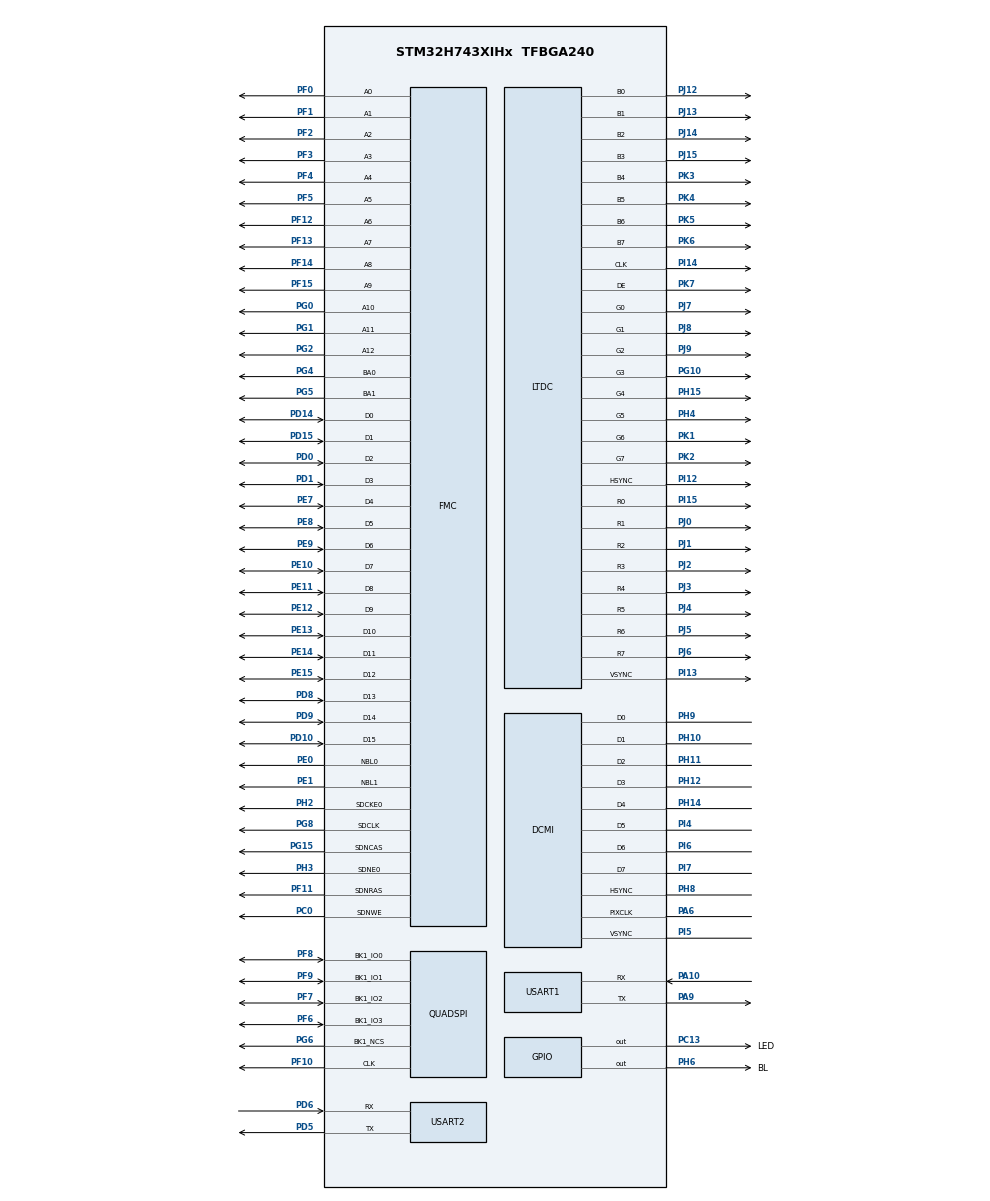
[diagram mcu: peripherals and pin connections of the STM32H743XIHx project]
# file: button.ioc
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CORTEX_M7.AccessPermission-Cortex_Memory_Protection_Unit_Region0_Settings=MPU_REGION_FULL_ACCESS
CORTEX_M7.AccessPermission_Spec=MPU_REGION_FULL_ACCESS
CORTEX_M7.BaseAddress-Cortex_Memory_Protection_Unit_Region0_Settings=0xC0000000
CORTEX_M7.BaseAddress_Spec=0xC0000000
CORTEX_M7.CPU_DCache=Enabled
CORTEX_M7.CPU_ICache=Enabled
CORTEX_M7.DisableExec_Spec=MPU_INSTRUCTION_ACCESS_ENABLE
CORTEX_M7.Enable-Cortex_Memory_Protection_Unit_Region0_Settings=MPU_REGION_ENABLE
CORTEX_M7.IsCacheable-Cortex_Memory_Protection_Unit_Region0_Settings=MPU_ACCESS_CACHEABLE
CORTEX_M7.IsCacheable_Spec=MPU_ACCESS_CACHEABLE
CORTEX_M7.IsShareable_Spec=MPU_ACCESS_NOT_SHAREABLE
CORTEX_M7.MPU_Control=MPU_HFNMI_PRIVDEF
CORTEX_M7.Size-Cortex_Memory_Protection_Unit_Region0_Settings=MPU_REGION_SIZE_32MB
CORTEX_M7.Size_Spec=MPU_REGION_SIZE_32MB
CORTEX_M7.SubRegionDisable_Spec=0x0
DCMI.PCKPolarity=DCMI_PCKPOLARITY_RISING
DMA2D.ColorMode=DMA2D_OUTPUT_RGB565
FMC.CASLatency1=FMC_SDRAM_CAS_LATENCY_3
FMC.ColumnBitsNumber1=FMC_SDRAM_COLUMN_BITS_NUM_9
FMC.ExitSelfRefreshDelay1=7
FMC.LoadToActiveDelay1=2
FMC.RCDDelay1=2 
FMC.RPDelay1=2
FMC.ReadBurst1=FMC_SDRAM_RBURST_ENABLE
FMC.ReadPipeDelay1=FMC_SDRAM_RPIPE_DELAY_1
FMC.RowCycleDelay1=7
FMC.SDClockPeriod1=FMC_SDRAM_CLOCK_PERIOD_2
FMC.SelfRefreshTime1=4
FMC.WriteRecoveryTime1=3
FREERTOS.Tasks01=TouchGFX_Task,0,4096,Start_TouchGFX_Task,Default,NULL,Dynamic,NULL,NULL;LED,-2,128,StartTaskLED,Default,NULL,Dynamic,NULL,NULL
FREERTOS.configMAX_PRIORITIES=14
FREERTOS.configTOTAL_HEAP_SIZE=32768
LTDC.ActiveW=800
LTDC.Alpha_L0=255
LTDC.FBStartAdress_L0=0xC0000000
LTDC.HBP=80
LTDC.HFP=200
LTDC.HSync=1
LTDC.ImageHeight_L0=480
LTDC.ImageWidth_L0=800
LTDC.Layers=0
LTDC.PixelFormat_L0=LTDC_PIXEL_FORMAT_RGB565
LTDC.VBP=20
LTDC.VFP=22
LTDC.VSync=1
LTDC.WindowX1_L0=800
LTDC.WindowY1_L0=480
Mcu.Family=STM32H7
Mcu.Name=STM32H743XIHx
Mcu.Package=TFBGA240
NVIC.DMA2D_IRQn=true\:6\:0\:true\:false\:true\:true\:true\:true\:true
NVIC.LTDC_IRQn=true\:6\:0\:true\:false\:true\:true\:true\:true\:true
NVIC.PriorityGroup=NVIC_PRIORITYGROUP_4
NVIC.TIM1_UP_IRQn=true\:15\:0\:false\:false\:true\:false\:false\:true\:true
NVIC.TimeBase=TIM1_UP_IRQn
NVIC.TimeBaseIP=TIM1
NVIC.USART2_IRQn=true\:5\:0\:false\:false\:true\:true\:true\:true\:true
PA10.Mode=Asynchronous
PA10.Signal=USART1_RX
PA13\ (JTMS/SWDIO).Mode=Serial_Wire
PA13\ (JTMS/SWDIO).Signal=DEBUG_JTMS-SWDIO
PA14\ (JTCK/SWCLK).Mode=Serial_Wire
PA14\ (JTCK/SWCLK).Signal=DEBUG_JTCK-SWCLK
PA6.GPIO_Speed=GPIO_SPEED_FREQ_VERY_HIGH
PA6.Mode=Slave_8_bits_External_Synchro
PA6.Signal=DCMI_PIXCLK
PA9.Mode=Asynchronous
PA9.Signal=USART1_TX
PC0.Signal=FMC_SDNWE
PC13.GPIO_Label=LED
PC13.Signal=GPIO_Output
PC14-OSC32_IN\ (OSC32_IN).Mode=LSE-External-Oscillator
PC14-OSC32_IN\ (OSC32_IN).Signal=RCC_OSC32_IN
PC15-OSC32_OUT\ (OSC32_OUT).Mode=LSE-External-Oscillator
PC15-OSC32_OUT\ (OSC32_OUT).Signal=RCC_OSC32_OUT
PD0.Signal=FMC_D2_DA2
PD1.Signal=FMC_D3_DA3
PD10.Signal=FMC_D15_DA15
PD14.Signal=FMC_D0_DA0
PD15.Signal=FMC_D1_DA1
PD5.Mode=Asynchronous
PD5.Signal=USART2_TX
PD6.Mode=Asynchronous
PD6.Signal=USART2_RX
PD8.Signal=FMC_D13_DA13
PD9.Signal=FMC_D14_DA14
PE0.Signal=FMC_NBL0
PE1.Signal=FMC_NBL1
PE10.Signal=FMC_D7_DA7
PE11.Signal=FMC_D8_DA8
PE12.Signal=FMC_D9_DA9
PE13.Signal=FMC_D10_DA10
PE14.Signal=FMC_D11_DA11
PE15.Signal=FMC_D12_DA12
PE7.Signal=FMC_D4_DA4
PE8.Signal=FMC_D5_DA5
PE9.Signal=FMC_D6_DA6
PF0.Signal=FMC_A0
PF1.Signal=FMC_A1
PF10.GPIO_Speed=GPIO_SPEED_FREQ_VERY_HIGH
PF10.Mode=Single Bank 1
PF10.Signal=QUADSPI_CLK
PF11.Signal=FMC_SDNRAS
PF12.Signal=FMC_A6
PF13.Signal=FMC_A7
PF14.Signal=FMC_A8
PF15.Signal=FMC_A9
PF2.Signal=FMC_A2
PF3.Signal=FMC_A3
PF4.Signal=FMC_A4
PF5.Signal=FMC_A5
PF6.GPIO_Speed=GPIO_SPEED_FREQ_VERY_HIGH
PF6.Mode=Single Bank 1
PF6.Signal=QUADSPI_BK1_IO3
PF7.GPIO_Speed=GPIO_SPEED_FREQ_VERY_HIGH
PF7.Mode=Single Bank 1
PF7.Signal=QUADSPI_BK1_IO2
PF8.GPIO_Speed=GPIO_SPEED_FREQ_VERY_HIGH
PF8.Mode=Single Bank 1
PF8.Signal=QUADSPI_BK1_IO0
PF9.GPIO_Speed=GPIO_SPEED_FREQ_VERY_HIGH
PF9.Mode=Single Bank 1
PF9.Signal=QUADSPI_BK1_IO1
PG0.Signal=FMC_A10
PG1.Signal=FMC_A11
PG10.GPIO_Speed=GPIO_SPEED_FREQ_VERY_HIGH
PG10.Mode=RGB888
PG10.Signal=LTDC_G3
PG15.Signal=FMC_SDNCAS
PG2.Signal=FMC_A12
PG4.Signal=FMC_A14_BA0
PG5.Signal=FMC_A15_BA1
PG6.GPIO_Speed=GPIO_SPEED_FREQ_VERY_HIGH
PG6.Mode=Single Bank 1
PG6.Signal=QUADSPI_BK1_NCS
PG8.Signal=FMC_SDCLK
PH0-OSC_IN\ (PH0).Mode=HSE-External-Oscillator
PH0-OSC_IN\ (PH0).Signal=RCC_OSC_IN
PH1-OSC_OUT\ (PH1).Mode=HSE-External-Oscillator
PH1-OSC_OUT\ (PH1).Signal=RCC_OSC_OUT
PH10.GPIO_Mode=GPIO_MODE_AF_PP
PH10.GPIO_PuPd=GPIO_NOPULL
PH10.GPIO_Speed=GPIO_SPEED_FREQ_VERY_HIGH
PH10.Mode=Slave_8_bits_External_Synchro
PH10.Signal=DCMI_D1
PH11.GPIO_Mode=GPIO_MODE_AF_PP
PH11.GPIO_PuPd=GPIO_NOPULL
PH11.GPIO_Speed=GPIO_SPEED_FREQ_VERY_HIGH
PH11.Mode=Slave_8_bits_External_Synchro
PH11.Signal=DCMI_D2
PH12.GPIO_Mode=GPIO_MODE_AF_PP
PH12.GPIO_PuPd=GPIO_NOPULL
PH12.GPIO_Speed=GPIO_SPEED_FREQ_VERY_HIGH
PH12.Mode=Slave_8_bits_External_Synchro
PH12.Signal=DCMI_D3
PH14.GPIO_Speed=GPIO_SPEED_FREQ_VERY_HIGH
PH14.Mode=Slave_8_bits_External_Synchro
PH14.Signal=DCMI_D4
PH15.GPIO_Speed=GPIO_SPEED_FREQ_VERY_HIGH
PH15.Mode=RGB888
PH15.Signal=LTDC_G4
PH2.Mode=SdramChipSelect1_1
PH2.Signal=FMC_SDCKE0
PH3.Mode=SdramChipSelect1_1
PH3.Signal=FMC_SDNE0
PH4.GPIO_Speed=GPIO_SPEED_FREQ_VERY_HIGH
PH4.Mode=RGB888
PH4.Signal=LTDC_G5
PH5.GPIO_Speed=GPIO_SPEED_FREQ_VERY_HIGH
PH5.Signal=SPI5_NSS
PH6.GPIO_Label=BL
PH6.PinState=GPIO_PIN_SET
PH6.Signal=GPIO_Output
PH8.GPIO_Speed=GPIO_SPEED_FREQ_VERY_HIGH
PH8.Mode=Slave_8_bits_External_Synchro
PH8.Signal=DCMI_HSYNC
PH9.GPIO_Mode=GPIO_MODE_AF_PP
PH9.GPIO_PuPd=GPIO_NOPULL
PH9.GPIO_Speed=GPIO_SPEED_FREQ_VERY_HIGH
PH9.Mode=Slave_8_bits_External_Synchro
PH9.Signal=DCMI_D0
PI12.GPIO_Speed=GPIO_SPEED_FREQ_VERY_HIGH
PI12.Mode=RGB888
PI12.Signal=LTDC_HSYNC
PI13.GPIO_Speed=GPIO_SPEED_FREQ_VERY_HIGH
PI13.Mode=RGB888
PI13.Signal=LTDC_VSYNC
PI14.GPIO_Speed=GPIO_SPEED_FREQ_VERY_HIGH
PI14.Mode=RGB888
PI14.Signal=LTDC_CLK
PI15.GPIO_Speed=GPIO_SPEED_FREQ_VERY_HIGH
PI15.Mode=RGB888
PI15.Signal=LTDC_R0
PI4.GPIO_Speed=GPIO_SPEED_FREQ_VERY_HIGH
PI4.Mode=Slave_8_bits_External_Synchro
PI4.Signal=DCMI_D5
PI5.GPIO_Speed=GPIO_SPEED_FREQ_VERY_HIGH
PI5.Mode=Slave_8_bits_External_Synchro
PI5.Signal=DCMI_VSYNC
PI6.GPIO_Speed=GPIO_SPEED_FREQ_VERY_HIGH
PI6.Mode=Slave_8_bits_External_Synchro
PI6.Signal=DCMI_D6
PI7.GPIO_Speed=GPIO_SPEED_FREQ_VERY_HIGH
PI7.Mode=Slave_8_bits_External_Synchro
PI7.Signal=DCMI_D7
PJ0.GPIO_Speed=GPIO_SPEED_FREQ_VERY_HIGH
PJ0.Mode=RGB888
PJ0.Signal=LTDC_R1
PJ1.GPIO_Speed=GPIO_SPEED_FREQ_VERY_HIGH
PJ1.Mode=RGB888
PJ1.Signal=LTDC_R2
PJ12.GPIO_Speed=GPIO_SPEED_FREQ_VERY_HIGH
PJ12.Mode=RGB888
PJ12.Signal=LTDC_B0
PJ13.GPIO_Speed=GPIO_SPEED_FREQ_VERY_HIGH
PJ13.Mode=RGB888
PJ13.Signal=LTDC_B1
PJ14.GPIO_Speed=GPIO_SPEED_FREQ_VERY_HIGH
PJ14.Mode=RGB888
PJ14.Signal=LTDC_B2
PJ15.GPIO_Speed=GPIO_SPEED_FREQ_VERY_HIGH
PJ15.Mode=RGB888
PJ15.Signal=LTDC_B3
PJ2.GPIO_Speed=GPIO_SPEED_FREQ_VERY_HIGH
PJ2.Mode=RGB888
PJ2.Signal=LTDC_R3
PJ3.GPIO_Speed=GPIO_SPEED_FREQ_VERY_HIGH
PJ3.Mode=RGB888
PJ3.Signal=LTDC_R4
PJ4.GPIO_Speed=GPIO_SPEED_FREQ_VERY_HIGH
PJ4.Mode=RGB888
PJ4.Signal=LTDC_R5
PJ5.GPIO_Speed=GPIO_SPEED_FREQ_VERY_HIGH
PJ5.Mode=RGB888
PJ5.Signal=LTDC_R6
PJ6.GPIO_Speed=GPIO_SPEED_FREQ_VERY_HIGH
PJ6.Mode=RGB888
PJ6.Signal=LTDC_R7
PJ7.GPIO_Speed=GPIO_SPEED_FREQ_VERY_HIGH
PJ7.Mode=RGB888
PJ7.Signal=LTDC_G0
PJ8.GPIO_Speed=GPIO_SPEED_FREQ_VERY_HIGH
PJ8.Mode=RGB888
PJ8.Signal=LTDC_G1
PJ9.GPIO_Speed=GPIO_SPEED_FREQ_VERY_HIGH
PJ9.Mode=RGB888
PJ9.Signal=LTDC_G2
PK1.GPIO_Speed=GPIO_SPEED_FREQ_VERY_HIGH
PK1.Mode=RGB888
PK1.Signal=LTDC_G6
PK2.GPIO_Speed=GPIO_SPEED_FREQ_VERY_HIGH
PK2.Mode=RGB888
PK2.Signal=LTDC_G7
PK3.GPIO_Speed=GPIO_SPEED_FREQ_VERY_HIGH
PK3.Mode=RGB888
PK3.Signal=LTDC_B4
PK4.GPIO_Speed=GPIO_SPEED_FREQ_VERY_HIGH
PK4.Mode=RGB888
PK4.Signal=LTDC_B5
PK5.GPIO_Speed=GPIO_SPEED_FREQ_VERY_HIGH
PK5.Mode=RGB888
PK5.Signal=LTDC_B6
PK6.GPIO_Speed=GPIO_SPEED_FREQ_VERY_HIGH
PK6.Mode=RGB888
PK6.Signal=LTDC_B7
PK7.GPIO_Speed=GPIO_SPEED_FREQ_VERY_HIGH
PK7.Mode=RGB888
PK7.Signal=LTDC_DE
ProjectManager.HeapSize=0x2000
ProjectManager.StackSize=0x2000
ProjectManager.TargetToolchain=STM32CubeIDE
QUADSPI.ClockMode=QSPI_CLOCK_MODE_3
QUADSPI.ClockPrescaler=1
QUADSPI.FifoThreshold=32
QUADSPI.FlashSize=22
QUADSPI.SampleShifting=QSPI_SAMPLE_SHIFTING_HALFCYCLE
RCC.ADCFreq_Value=50390625
RCC.APB1Freq_Value=120000000
RCC.APB2Freq_Value=120000000
RCC.APB3Freq_Value=120000000
RCC.APB4Freq_Value=120000000
RCC.CortexFreq_Value=480000000
RCC.D1PPRE=RCC_APB3_DIV2
RCC.D2PPRE1=RCC_APB1_DIV2
RCC.D2PPRE2=RCC_APB2_DIV2
RCC.D3PPRE=RCC_APB4_DIV2
RCC.DIVM1=5
RCC.DIVM3=25
RCC.DIVN1=192
RCC.DIVN3=330
RCC.DIVQ1=4
RCC.DIVR3=10
RCC.HCLKFreq_Value=240000000
RCC.HPRE=RCC_HCLK_DIV2
RCC.PLLSourceVirtual=RCC_PLLSOURCE_HSE
RCC.PWR_Regulator_Voltage_Scale=PWR_REGULATOR_VOLTAGE_SCALE0
RCC.ProductRev=revV
RCC.RTCClockSelection=RCC_RTCCLKSOURCE_LSE
RCC.SYSCLKFreq_VALUE=480000000
RCC.SYSCLKSource=RCC_SYSCLKSOURCE_PLLCLK
RCC.USBFreq_Value=240000000
SH.FMC_A0.0=FMC_A0,13b-sda1
SH.FMC_A1.0=FMC_A1,13b-sda1
SH.FMC_A10.0=FMC_A10,13b-sda1
SH.FMC_A11.0=FMC_A11,13b-sda1
SH.FMC_A12.0=FMC_A12,13b-sda1
SH.FMC_A14_BA0.0=FMC_BA0,FourSdramBanks1
SH.FMC_A15_BA1.0=FMC_BA1,FourSdramBanks1
SH.FMC_A2.0=FMC_A2,13b-sda1
SH.FMC_A3.0=FMC_A3,13b-sda1
SH.FMC_A4.0=FMC_A4,13b-sda1
SH.FMC_A5.0=FMC_A5,13b-sda1
SH.FMC_A6.0=FMC_A6,13b-sda1
SH.FMC_A7.0=FMC_A7,13b-sda1
SH.FMC_A8.0=FMC_A8,13b-sda1
SH.FMC_A9.0=FMC_A9,13b-sda1
SH.FMC_D0_DA0.0=FMC_D0,sd-16b-d1
SH.FMC_D10_DA10.0=FMC_D10,sd-16b-d1
SH.FMC_D11_DA11.0=FMC_D11,sd-16b-d1
SH.FMC_D12_DA12.0=FMC_D12,sd-16b-d1
SH.FMC_D13_DA13.0=FMC_D13,sd-16b-d1
SH.FMC_D14_DA14.0=FMC_D14,sd-16b-d1
SH.FMC_D15_DA15.0=FMC_D15,sd-16b-d1
SH.FMC_D1_DA1.0=FMC_D1,sd-16b-d1
SH.FMC_D2_DA2.0=FMC_D2,sd-16b-d1
SH.FMC_D3_DA3.0=FMC_D3,sd-16b-d1
SH.FMC_D4_DA4.0=FMC_D4,sd-16b-d1
SH.FMC_D5_DA5.0=FMC_D5,sd-16b-d1
SH.FMC_D6_DA6.0=FMC_D6,sd-16b-d1
SH.FMC_D7_DA7.0=FMC_D7,sd-16b-d1
SH.FMC_D8_DA8.0=FMC_D8,sd-16b-d1
SH.FMC_D9_DA9.0=FMC_D9,sd-16b-d1
SH.FMC_NBL0.0=FMC_NBL0,Sd2ByteEnable1
SH.FMC_NBL1.0=FMC_NBL1,Sd2ByteEnable1
SH.FMC_SDCLK.0=FMC_SDCLK,13b-sda1
SH.FMC_SDNCAS.0=FMC_SDNCAS,13b-sda1
SH.FMC_SDNRAS.0=FMC_SDNRAS,13b-sda1
SH.FMC_SDNWE.0=FMC_SDNWE,13b-sda1
STMicroelectronics.X-CUBE-TOUCHGFX.4.23.2.ApplicationCcGraphicsJjApplication=TouchGFXOoGenerator
STMicroelectronics.X-CUBE-TOUCHGFX.4.23.2.tgfx_address1=0xC0000000
STMicroelectronics.X-CUBE-TOUCHGFX.4.23.2.tgfx_address2=0xC00BB800
STMicroelectronics.X-CUBE-TOUCHGFX.4.23.2.tgfx_buffering_strategy=Double
STMicroelectronics.X-CUBE-TOUCHGFX.4.23.2.tgfx_display_interface=disp_ltdc
STMicroelectronics.X-CUBE-TOUCHGFX.4.23.2.tgfx_hardware_accelerator=dma_2d
STMicroelectronics.X-CUBE-TOUCHGFX.4.23.2.tgfx_location=By Address
STMicroelectronics.X-CUBE-TOUCHGFX.4.23.2.tgfx_vsync=vsync_ltdc
STMicroelectronics.X-CUBE-TOUCHGFX.4.23.2_IsPackSelfContextualization=true
USART1.VirtualMode-Asynchronous=VM_ASYNC
USART2.VirtualMode-Asynchronous=VM_ASYNC
VP_CRC_VS_CRC.Mode=CRC_Activate
VP_DMA2D_VS_DMA2D.Mode=DMA2D_Activate
VP_FREERTOS_VS_CMSIS_V1.Mode=CMSIS_V1
VP_RTC_VS_RTC_Activate.Mode=RTC_Enabled
VP_STMicroelectronics.X-CUBE-TOUCHGFX_VS_GraphicsJjApplication_4.23.2.Mode=GraphicsJjApplication
VP_SYS_VS_tim1.Mode=TIM1
board=custom

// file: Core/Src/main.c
/* USER CODE BEGIN Header */
/**
  ******************************************************************************
  * @file           : main.c
  * @brief          : Main program body
  ******************************************************************************
  * @attention
  *
  * Copyright (c) 2024 STMicroelectronics.
  * All rights reserved.
  *
  * This software is licensed under terms that can be found in the LICENSE file
  * in the root directory of this software component.
  * If no LICENSE file comes with this software, it is provided AS-IS.
  *
  ******************************************************************************
  */
/* USER CODE END Header */
#include "main.h"
#include "cmsis_os.h"
#include "crc.h"
#include "dcmi.h"
#include "dma2d.h"
#include "ltdc.h"
#include "quadspi.h"
#include "rtc.h"
#include "usart.h"
#include "gpio.h"
#include "fmc.h"
#include "app_touchgfx.h"

/* USER CODE BEGIN Includes */
#include "stdio.h"
#include "sdram.h"
#include "qspi_w25q64.h"
#include "ov5640.h"

/* USER CODE END Includes */

void SystemClock_Config(void);
static void MPU_Config(void);
void MX_FREERTOS_Init(void);

/* USER CODE BEGIN 0 */
int flag_usart = 0;
int flag_ok = 0;
/* USER CODE END 0 */

int main(void)
{

  /* MPU Configuration--------------------------------------------------------*/
  MPU_Config();

  /* Enable the CPU Cache */

  /* Enable I-Cache---------------------------------------------------------*/
  SCB_EnableICache();

  /* Enable D-Cache---------------------------------------------------------*/
  SCB_EnableDCache();

  /* MCU Configuration--------------------------------------------------------*/

  /* Reset of all peripherals, Initializes the Flash interface and the Systick. */
  HAL_Init();

  /* Configure the system clock */
  SystemClock_Config();

  /* Initialize all configured peripherals */
  MX_GPIO_Init();
  MX_RTC_Init();
  MX_DMA2D_Init();
  MX_FMC_Init();
  MX_QUADSPI_Init();
  MX_USART1_UART_Init();
  MX_LTDC_Init();
  MX_CRC_Init();
  MX_USART2_UART_Init();
  MX_DCMI_Init();
  MX_TouchGFX_Init();
  /* Call PreOsInit function */
  MX_TouchGFX_PreOSInit();
  /* USER CODE BEGIN 2 */
  QSPI_W25Qxx_MemoryMappedMode(&hqspi);		// 进入内存映射模式

  /* USER CODE END 2 */

  /* Call init function for freertos objects (in cmsis_os2.c) */
  MX_FREERTOS_Init();

  /* Start scheduler */
  osKernelStart();

  /* We should never get here as control is now taken by the scheduler */

  /* Infinite loop */
  while (1)
  {

  }
}

void SystemClock_Config(void)
{
  RCC_OscInitTypeDef RCC_OscInitStruct = {0};
  RCC_ClkInitTypeDef RCC_ClkInitStruct = {0};

  /** Supply configuration update enable
  */
  HAL_PWREx_ConfigSupply(PWR_LDO_SUPPLY);

  /** Configure the main internal regulator output voltage
  */
  __HAL_PWR_VOLTAGESCALING_CONFIG(PWR_REGULATOR_VOLTAGE_SCALE1);

  while(!__HAL_PWR_GET_FLAG(PWR_FLAG_VOSRDY)) {}

  __HAL_RCC_SYSCFG_CLK_ENABLE();
  __HAL_PWR_VOLTAGESCALING_CONFIG(PWR_REGULATOR_VOLTAGE_SCALE0);

  while(!__HAL_PWR_GET_FLAG(PWR_FLAG_VOSRDY)) {}

  /** Configure LSE Drive Capability
  */
  HAL_PWR_EnableBkUpAccess();
  __HAL_RCC_LSEDRIVE_CONFIG(RCC_LSEDRIVE_LOW);

  /** Initializes the RCC Oscillators according to the specified parameters
  * in the RCC_OscInitTypeDef structure.
  */
  RCC_OscInitStruct.OscillatorType = RCC_OSCILLATORTYPE_HSE|RCC_OSCILLATORTYPE_LSE;
  RCC_OscInitStruct.HSEState = RCC_HSE_ON;
  RCC_OscInitStruct.LSEState = RCC_LSE_ON;
  RCC_OscInitStruct.PLL.PLLState = RCC_PLL_ON;
  RCC_OscInitStruct.PLL.PLLSource = RCC_PLLSOURCE_HSE;
  RCC_OscInitStruct.PLL.PLLM = 5;
  RCC_OscInitStruct.PLL.PLLN = 192;
  RCC_OscInitStruct.PLL.PLLP = 2;
  RCC_OscInitStruct.PLL.PLLQ = 4;
  RCC_OscInitStruct.PLL.PLLR = 2;
  RCC_OscInitStruct.PLL.PLLRGE = RCC_PLL1VCIRANGE_2;
  RCC_OscInitStruct.PLL.PLLVCOSEL = RCC_PLL1VCOWIDE;
  RCC_OscInitStruct.PLL.PLLFRACN = 0;
  if (HAL_RCC_OscConfig(&RCC_OscInitStruct) != HAL_OK)
  {
    Error_Handler();
  }

  /** Initializes the CPU, AHB and APB buses clocks
  */
  RCC_ClkInitStruct.ClockType = RCC_CLOCKTYPE_HCLK|RCC_CLOCKTYPE_SYSCLK
                              |RCC_CLOCKTYPE_PCLK1|RCC_CLOCKTYPE_PCLK2
                              |RCC_CLOCKTYPE_D3PCLK1|RCC_CLOCKTYPE_D1PCLK1;
  RCC_ClkInitStruct.SYSCLKSource = RCC_SYSCLKSOURCE_PLLCLK;
  RCC_ClkInitStruct.SYSCLKDivider = RCC_SYSCLK_DIV1;
  RCC_ClkInitStruct.AHBCLKDivider = RCC_HCLK_DIV2;
  RCC_ClkInitStruct.APB3CLKDivider = RCC_APB3_DIV2;
  RCC_ClkInitStruct.APB1CLKDivider = RCC_APB1_DIV2;
  RCC_ClkInitStruct.APB2CLKDivider = RCC_APB2_DIV2;
  RCC_ClkInitStruct.APB4CLKDivider = RCC_APB4_DIV2;

  if (HAL_RCC_ClockConfig(&RCC_ClkInitStruct, FLASH_LATENCY_4) != HAL_OK)
  {
    Error_Handler();
  }
}

 /* MPU Configuration */

void MPU_Config(void)
{
  MPU_Region_InitTypeDef MPU_InitStruct = {0};

  /* Disables the MPU */
  HAL_MPU_Disable();

  /** Initializes and configures the Region and the memory to be protected
  */
  MPU_InitStruct.Enable = MPU_REGION_ENABLE;
  MPU_InitStruct.Number = MPU_REGION_NUMBER0;
  MPU_InitStruct.BaseAddress = 0xC0000000;
  MPU_InitStruct.Size = MPU_REGION_SIZE_32MB;
  MPU_InitStruct.SubRegionDisable = 0x0;
  MPU_InitStruct.TypeExtField = MPU_TEX_LEVEL0;
  MPU_InitStruct.AccessPermission = MPU_REGION_FULL_ACCESS;
  MPU_InitStruct.DisableExec = MPU_INSTRUCTION_ACCESS_ENABLE;
  MPU_InitStruct.IsShareable = MPU_ACCESS_NOT_SHAREABLE;
  MPU_InitStruct.IsCacheable = MPU_ACCESS_CACHEABLE;
  MPU_InitStruct.IsBufferable = MPU_ACCESS_NOT_BUFFERABLE;

  HAL_MPU_ConfigRegion(&MPU_InitStruct);
  /* Enables the MPU */
  HAL_MPU_Enable(MPU_HFNMI_PRIVDEF);

}

void HAL_TIM_PeriodElapsedCallback(TIM_HandleTypeDef *htim)
{
  if (htim->Instance == TIM1) {
    HAL_IncTick();
  }
}

void Error_Handler(void)
{
  __disable_irq();
  while (1)
  {
  }
}

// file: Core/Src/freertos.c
/* USER CODE BEGIN Header */
/**
  ******************************************************************************
  * File Name          : freertos.c
  * Description        : Code for freertos applications
  ******************************************************************************
  * @attention
  *
  * Copyright (c) 2024 STMicroelectronics.
  * All rights reserved.
  *
  * This software is licensed under terms that can be found in the LICENSE file
  * in the root directory of this software component.
  * If no LICENSE file comes with this software, it is provided AS-IS.
  *
  ******************************************************************************
  */
/* USER CODE END Header */

#include "FreeRTOS.h"
#include "task.h"
#include "main.h"
#include "cmsis_os.h"

/* USER CODE BEGIN Includes */
#include "app_touchgfx.h"
#include "usart.h"
#include "stdio.h"
/* USER CODE END Includes */

/* USER CODE BEGIN PTD */
DataPacket packet;
int ECG_flag;
uint8_t rx_buffer[172];

/* USER CODE END PTD */

/* USER CODE BEGIN PD */

uint32_t unpack_uint32(const uint8_t *data) {
    // 确保从小端字节序数据中提取一�?32位无符号整数
    return (uint32_t)data[0] |
           (uint32_t)data[1] << 8 |
           (uint32_t)data[2] << 16 |
           (uint32_t)data[3] << 24;
}

void unpack_data(const uint8_t *data, DataPacket *packet) {
    // 复制ECG数据
    for (int i = 0; i < ECG_DATA_SIZE; i++) {
        packet->ecg_data[i] = unpack_uint32(data);
        data += 4;
    }

    // 复制心率
    packet->heart_rate = unpack_uint32(data);
    data += 4;

    // 复制体温
    packet->body_temperature = unpack_uint32(data);
    data += 4;

    // 复制�?�?
    packet->blood_oxygen = unpack_uint32(data);
}

void print_packet(const DataPacket *packet) {
    printf("ECG Data: ");
    for (int i = 0; i < ECG_DATA_SIZE; i++) {
        printf("%u ", packet->ecg_data[i]);
    }
    printf("\n");

    printf("Heart Rate: %u\n", packet->heart_rate);
    printf("Body Temperature: %u\n", packet->body_temperature);
    printf("Blood Oxygen: %u\n", packet->blood_oxygen);
}

uint8_t data[] = {
        // ecg_data[40]
        0x01, 0x00, 0x00, 0x00, // 1
        0x02, 0x00, 0x00, 0x00, // 2
        0x03, 0x00, 0x00, 0x00, // 3
        0x04, 0x00, 0x00, 0x00, // 4
        0x05, 0x00, 0x00, 0x00, // 5
        0x06, 0x00, 0x00, 0x00, // 6
        0x07, 0x00, 0x00, 0x00, // 7
        0x08, 0x00, 0x00, 0x00, // 8
        0x09, 0x00, 0x00, 0x00, // 9
        0x0A, 0x00, 0x00, 0x00, // 10
        0x0B, 0x00, 0x00, 0x00, // 11
        0x0C, 0x00, 0x00, 0x00, // 12
        0x0D, 0x00, 0x00, 0x00, // 13
        0x0E, 0x00, 0x00, 0x00, // 14
        0x0F, 0x00, 0x00, 0x00, // 15
        0x10, 0x00, 0x00, 0x00, // 16
        0x11, 0x00, 0x00, 0x00, // 17
        0x12, 0x00, 0x00, 0x00, // 18
        0x13, 0x00, 0x00, 0x00, // 19
        0x14, 0x00, 0x00, 0x00, // 20
        0x15, 0x00, 0x00, 0x00, // 21
        0x16, 0x00, 0x00, 0x00, // 22
        0x17, 0x00, 0x00, 0x00, // 23
        0x18, 0x00, 0x00, 0x00, // 24
        0x19, 0x00, 0x00, 0x00, // 25
        0x1A, 0x00, 0x00, 0x00, // 26
        0x1B, 0x00, 0x00, 0x00, // 27
        0x1C, 0x00, 0x00, 0x00, // 28
        0x1D, 0x00, 0x00, 0x00, // 29
        0x1E, 0x00, 0x00, 0x00, // 30
        0x1F, 0x00, 0x00, 0x00, // 31
        0x20, 0x00, 0x00, 0x00, // 32
        0x21, 0x00, 0x00, 0x00, // 33
        0x22, 0x00, 0x00, 0x00, // 34
        0x23, 0x00, 0x00, 0x00, // 35
        0x24, 0x00, 0x00, 0x00, // 36
        0x25, 0x00, 0x00, 0x00, // 37
        0x26, 0x00, 0x00, 0x00, // 38
        0x27, 0x00, 0x00, 0x00, // 39
        0x28, 0x00, 0x00, 0x00, // 40
        0x2C, 0x01, 0x00, 0x00, // heart_rate 300
        0x90, 0x01, 0x00, 0x00, // body_temperature 400
        0x5E, 0x01, 0x00, 0x00  // blood_oxygen 350
    };

/* USER CODE END PD */

osThreadId TouchGFX_TaskHandle;
osThreadId LEDHandle;

void Start_TouchGFX_Task(void const * argument);
void StartTaskLED(void const * argument);

void MX_FREERTOS_Init(void); /* (MISRA C 2004 rule 8.1) */

/* GetIdleTaskMemory prototype (linked to static allocation support) */
void vApplicationGetIdleTaskMemory( StaticTask_t **ppxIdleTaskTCBBuffer, StackType_t **ppxIdleTaskStackBuffer, uint32_t *pulIdleTaskStackSize );

/* USER CODE BEGIN GET_IDLE_TASK_MEMORY */
static StaticTask_t xIdleTaskTCBBuffer;
static StackType_t xIdleStack[configMINIMAL_STACK_SIZE];

void vApplicationGetIdleTaskMemory( StaticTask_t **ppxIdleTaskTCBBuffer, StackType_t **ppxIdleTaskStackBuffer, uint32_t *pulIdleTaskStackSize )
{
  *ppxIdleTaskTCBBuffer = &xIdleTaskTCBBuffer;
  *ppxIdleTaskStackBuffer = &xIdleStack[0];
  *pulIdleTaskStackSize = configMINIMAL_STACK_SIZE;
  /* place for user code */
}
/* USER CODE END GET_IDLE_TASK_MEMORY */

void MX_FREERTOS_Init(void) {
  /* USER CODE BEGIN Init */
//  Wifi_Init(osPriorityNormal);

  /* USER CODE END Init */

  /* Create the thread(s) */
  /* definition and creation of TouchGFX_Task */
  osThreadDef(TouchGFX_Task, Start_TouchGFX_Task, osPriorityNormal, 0, 4096);
  TouchGFX_TaskHandle = osThreadCreate(osThread(TouchGFX_Task), NULL);

  /* definition and creation of LED */
  osThreadDef(LED, StartTaskLED, osPriorityLow, 0, 128);
  LEDHandle = osThreadCreate(osThread(LED), NULL);

}

void Start_TouchGFX_Task(void const * argument)
{
  /* USER CODE BEGIN Start_TouchGFX_Task */
	MX_TouchGFX_Process();
  /* Infinite loop */
  for(;;)
  {
    osDelay(50);
  }
  /* USER CODE END Start_TouchGFX_Task */
}

void StartTaskLED(void const * argument)
{
  /* USER CODE BEGIN StartTaskLED */

  /* Infinite loop */
  for(;;)
  {
      HAL_GPIO_TogglePin(LED_GPIO_Port, LED_Pin);

      HAL_UART_Receive_IT(&huart2, rx_buffer, 172);

      osDelay(50);
  /* USER CODE END StartTaskLED */
}
}
/* USER CODE BEGIN Application */

void HAL_UART_RxCpltCallback(UART_HandleTypeDef *huart)
{

	unpack_data(rx_buffer, &packet);
	print_packet(&packet);
}
/* USER CODE END Application */
